AUTOSAR XML (schema 00049)
package /ARRoot
  elements flat-map=instances=flat-instance-descriptor=SystemExtract2_SWComp.SystemExtract_2:
    system SystemExtract_2
      system mapping VehSpdActrSystemMaping: swc-to-impl-mapping=component=VehSpdActrComp.SystemExtract2_SWComp.SystemExtract2_SWComp, swc-to-ecu-mapping=component=VehSpdActrComp.SystemExtract2_SWComp.SystemExtract2_SWComp
        data-mappings:
          communication-direction=IN, data-element=SystemExtract2_SWComp.VehSpdActrComp.VehSpdInput_RPort.UINT8
          communication-direction=OUT, data-element=SystemExtract2_SWComp.VehSpdActrComp.Led1Output_PPort.UINT8
          communication-direction=OUT, data-element=SystemExtract2_SWComp.VehSpdActrComp.Led0Output_PPort.UINT8
      system mapping VehSpdVirtSystemMaping: swc-to-impl-mapping=component=VehSpdVirtComp.SystemExtract2_SWComp.SystemExtract2_SWComp, swc-to-ecu-mapping=component=VehSpdVirtComp.SystemExtract2_SWComp.SystemExtract2_SWComp
        data-mappings:
          communication-direction=IN, data-element=SystemExtract2_SWComp.VehSpdVirtComp.Led0Input_RPort.BOOL
          communication-direction=IN, data-element=SystemExtract2_SWComp.VehSpdVirtComp.Led1Input_RPort.BOOL
      root-software-compositions:
        root sw composition prototype VehSpdActrComp
        root sw composition prototype VehSpdVirtComp: software-composition=TopLevelSystemExtract2
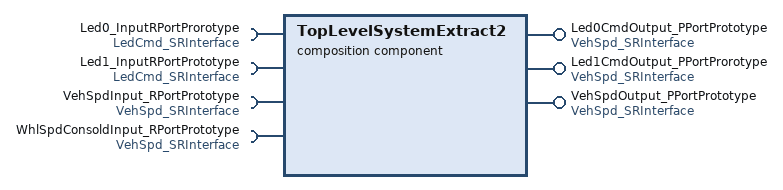
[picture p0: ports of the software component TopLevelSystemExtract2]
    composition sw component type TopLevelSystemExtract2
      provide port Led0CmdOutput_PPortPrototype: provided-interface=VehSpd_SRInterface
      require port Led0_InputRPortProrotype: required-interface=LedCmd_SRInterface
      provide port Led1CmdOutput_PPortProrotype: provided-interface=VehSpd_SRInterface
      require port Led1_InputRPortPrototype: required-interface=LedCmd_SRInterface
      require port VehSpdInput_RPortPrototype: required-interface=VehSpd_SRInterface
      provide port VehSpdOutput_PPortPrototype: provided-interface=VehSpd_SRInterface
      require port WhlSpdConsoldInput_RPortPrototype: required-interface=VehSpd_SRInterface
      component SystemExtract2_SWComp: type=TopLevelSystemExtract2
      assembly sw connector Led0CmdOutput_Connector: provider=SystemExtract2_SWComp.Led0CmdOutput_PPortPrototype
      assembly sw connector Led0Input_Connector: requester=SystemExtract2_SWComp.Led0_InputRPortProrotype
      assembly sw connector Led1CmdOutput_Connector: provider=SystemExtract2_SWComp.Led1CmdOutput_PPortProrotype
      assembly sw connector Led1Input_Connector: requester=SystemExtract2_SWComp.Led1_InputRPortPrototype
      assembly sw connector VehSpdInput_Connector: requester=SystemExtract2_SWComp.VehSpdInput_RPortPrototype
      assembly sw connector VehSpdOutput_Connector: provider=SystemExtract2_SWComp.VehSpdOutput_PPortPrototype
      assembly sw connector WehSpdConsoldInput_Connector: requester=SystemExtract2_SWComp.WhlSpdConsoldInput_RPortPrototype
    can cluster VehSpdActr_CANCluster: can-physical-channel=comm-connectors=VehSpdActr_Connector
    ecu instance VehSpdActr_ECUInstance
      can communication controller VehSpdActr_Controller
      can communication connector VehSpdActr_Connector: comm-controller=VehSpdActr_Controller
    can cluster VehSpdCalc_CANCluster: can-physical-channel=comm-connectors=VehSpdCalc_Connector
    ecu instance VehSpdCalc_ECUInstance
      can communication controller VehSpdCalc_Controller
      can communication connector VehSpdCalc_Connector: comm-controller=VehSpdCalc_Controller
    can cluster VehSpdVirt_CANCluseter: can-physical-channel=comm-connectors=VehSpdVirtConnector
    ecu instance VehSpdVirt_ECUInstance
      can communication controller VehSpdVirtController
      can communication connector VehSpdVirtConnector: comm-controller=VehSpdVirtController
